AUTOSAR XML (schema 4-2-2)
package /STELLANTIS/EPT/ASWCs
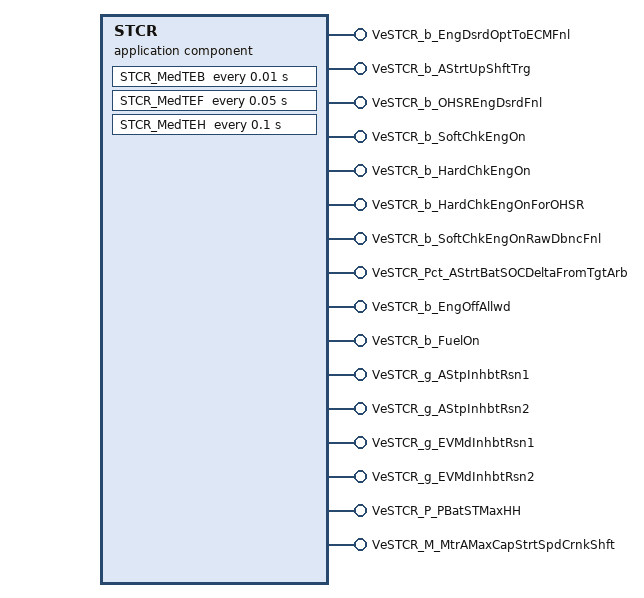
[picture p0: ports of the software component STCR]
  application sw component type STCR
    16 x provide port, all with nonqueued-sender-com-spec{data-element=Value, init-value=0}:
      VeSTCR_b_EngDsrdOptToECMFnl: provided-interface=VeSTCR_b_EngDsrdOptToECMFnl
      VeSTCR_b_AStrtUpShftTrg: provided-interface=VeSTCR_b_AStrtUpShftTrg
      VeSTCR_b_OHSREngDsrdFnl: provided-interface=VeSTCR_b_OHSREngDsrdFnl
      VeSTCR_b_SoftChkEngOn: provided-interface=VeSTCR_b_SoftChkEngOn
      VeSTCR_b_HardChkEngOn: provided-interface=VeSTCR_b_HardChkEngOn
      VeSTCR_b_HardChkEngOnForOHSR: provided-interface=VeSTCR_b_HardChkEngOnForOHSR
      VeSTCR_b_SoftChkEngOnRawDbncFnl: provided-interface=VeSTCR_b_SoftChkEngOnRawDbncFnl
      VeSTCR_Pct_AStrtBatSOCDeltaFromTgtArb: provided-interface=VeSTCR_Pct_AStrtBatSOCDeltaFromTgtArb
      VeSTCR_b_EngOffAllwd: provided-interface=VeSTCR_b_EngOffAllwd
      VeSTCR_b_FuelOn: provided-interface=VeSTCR_b_FuelOn
      VeSTCR_g_AStpInhbtRsn1: provided-interface=VeSTCR_g_AStpInhbtRsn1
      VeSTCR_g_AStpInhbtRsn2: provided-interface=VeSTCR_g_AStpInhbtRsn2
      VeSTCR_g_EVMdInhbtRsn1: provided-interface=VeSTCR_g_EVMdInhbtRsn1
      VeSTCR_g_EVMdInhbtRsn2: provided-interface=VeSTCR_g_EVMdInhbtRsn2
      VeSTCR_P_PBatSTMaxHH: provided-interface=VeSTCR_P_PBatSTMaxHH
      VeSTCR_M_MtrAMaxCapStrtSpdCrnkShft: provided-interface=VeSTCR_M_MtrAMaxCapStrtSpdCrnkShft
    behavior IB_STCR: data-type-mapping=msADTtoIDTMapping, handle-termination-and-restart=NO-SUPPORT
      timing event Event_MedTEB: start-on-event=STCR_MedTEB, period=0.01
      timing event Event_MedTEF: start-on-event=STCR_MedTEF, period=0.05
      timing event Event_MedTEH: start-on-event=STCR_MedTEH, period=0.1
      init event Event_STCR_ac_Init: start-on-event=STCR_ac_Init
      init event Event_PwrOn: start-on-event=STCR_PwrOn
      explicit-inter-runnable-variables:
        6 x data, all with category=VALUE, sw-calibration-access=READ-ONLY, type=Boolean, init-value=0:
          VeSTCR_b_EngOffAlwdSlow_write_IRV
          VeSTCR_b_EngOffAlwdHardChk_write_IRV
          VeSTCR_b_EngOnFuelOn_write_IRV
          VeSTCR_b_SoftChkEngOnFuelOn_write_IRV
          VeSTCR_b_DCOvrld_EngOn_write_IRV
          VeSTCR_b_V2L_EngON_write_IRV
      5 x runnable:
        STCR_ac_Init
        STCR_MedTEB
          data-send-points:
            12 x access:
              OUT_VeSTCR_P_PBatSTMaxHH_Value: accessed-variable=VeSTCR_P_PBatSTMaxHH.Value
              OUT_VeSTCR_b_EngDsrdOptToECMFnl_Value: accessed-variable=VeSTCR_b_EngDsrdOptToECMFnl.Value
              OUT_VeSTCR_b_AStrtUpShftTrg_Value: accessed-variable=VeSTCR_b_AStrtUpShftTrg.Value
              OUT_VeSTCR_b_OHSREngDsrdFnl_Value: accessed-variable=VeSTCR_b_OHSREngDsrdFnl.Value
              OUT_VeSTCR_b_SoftChkEngOn_Value: accessed-variable=VeSTCR_b_SoftChkEngOn.Value
              OUT_VeSTCR_b_SoftChkEngOnRawDbncFnl_Value: accessed-variable=VeSTCR_b_SoftChkEngOnRawDbncFnl.Value
              OUT_VeSTCR_b_EngOffAllwd_Value: accessed-variable=VeSTCR_b_EngOffAllwd.Value
              OUT_VeSTCR_b_FuelOn_Value: accessed-variable=VeSTCR_b_FuelOn.Value
              OUT_VeSTCR_g_AStpInhbtRsn1_Value: accessed-variable=VeSTCR_g_AStpInhbtRsn1.Value
              OUT_VeSTCR_g_AStpInhbtRsn2_Value: accessed-variable=VeSTCR_g_AStpInhbtRsn2.Value
              OUT_VeSTCR_g_EVMdInhbtRsn1_Value: accessed-variable=VeSTCR_g_EVMdInhbtRsn1.Value
              OUT_VeSTCR_g_EVMdInhbtRsn2_Value: accessed-variable=VeSTCR_g_EVMdInhbtRsn2.Value
          read-local-variables:
            4 x access:
              RV_VeSTCR_b_EngOffAlwdHardChk_write_IRV: accessed-variable=VeSTCR_b_EngOffAlwdHardChk_write_IRV
              RV_VeSTCR_b_EngOffAlwdSlow_write_IRV: accessed-variable=VeSTCR_b_EngOffAlwdSlow_write_IRV
              RV_VeSTCR_b_EngOnFuelOn_write_IRV: accessed-variable=VeSTCR_b_EngOnFuelOn_write_IRV
              RV_VeSTCR_b_SoftChkEngOnFuelOn_write_IRV: accessed-variable=VeSTCR_b_SoftChkEngOnFuelOn_write_IRV
          written-local-variables:
            access WV_VeSTCR_b_DCOvrld_EngOn_write_IRV: accessed-variable=VeSTCR_b_DCOvrld_EngOn_write_IRV
            access WV_VeSTCR_b_V2L_EngON_write_IRV: accessed-variable=VeSTCR_b_V2L_EngON_write_IRV
        STCR_MedTEF
          data-send-points:
            access OUT_VeSTCR_b_HardChkEngOn_Value: accessed-variable=VeSTCR_b_HardChkEngOn.Value
            access OUT_VeSTCR_b_HardChkEngOnForOHSR_Value: accessed-variable=VeSTCR_b_HardChkEngOnForOHSR.Value
            access OUT_VeSTCR_M_MtrAMaxCapStrtSpdCrnkShft_Value: accessed-variable=VeSTCR_M_MtrAMaxCapStrtSpdCrnkShft.Value
          written-local-variables:
            access WV_VeSTCR_b_EngOffAlwdHardChk_write_IRV: accessed-variable=VeSTCR_b_EngOffAlwdHardChk_write_IRV
            access WV_VeSTCR_b_EngOnFuelOn_write_IRV: accessed-variable=VeSTCR_b_EngOnFuelOn_write_IRV
        STCR_MedTEH
          data-send-points:
            access OUT_VeSTCR_Pct_AStrtBatSOCDeltaFromTgtArb_Value: accessed-variable=VeSTCR_Pct_AStrtBatSOCDeltaFromTgtArb.Value
          written-local-variables:
            access WV_VeSTCR_b_EngOffAlwdSlow_write_IRV: accessed-variable=VeSTCR_b_EngOffAlwdSlow_write_IRV
            access WV_VeSTCR_b_SoftChkEngOnFuelOn_write_IRV: accessed-variable=VeSTCR_b_SoftChkEngOnFuelOn_write_IRV
        STCR_PwrOn
          data-send-points:
            16 x access:
              OUT_VeSTCR_b_EngDsrdOptToECMFnl_Value: accessed-variable=VeSTCR_b_EngDsrdOptToECMFnl.Value
              OUT_VeSTCR_b_AStrtUpShftTrg_Value: accessed-variable=VeSTCR_b_AStrtUpShftTrg.Value
              OUT_VeSTCR_b_OHSREngDsrdFnl_Value: accessed-variable=VeSTCR_b_OHSREngDsrdFnl.Value
              OUT_VeSTCR_b_SoftChkEngOn_Value: accessed-variable=VeSTCR_b_SoftChkEngOn.Value
              OUT_VeSTCR_b_HardChkEngOn_Value: accessed-variable=VeSTCR_b_HardChkEngOn.Value
              OUT_VeSTCR_b_HardChkEngOnForOHSR_Value: accessed-variable=VeSTCR_b_HardChkEngOnForOHSR.Value
              OUT_VeSTCR_b_SoftChkEngOnRawDbncFnl_Value: accessed-variable=VeSTCR_b_SoftChkEngOnRawDbncFnl.Value
              OUT_VeSTCR_Pct_AStrtBatSOCDeltaFromTgtArb_Value: accessed-variable=VeSTCR_Pct_AStrtBatSOCDeltaFromTgtArb.Value
              OUT_VeSTCR_b_EngOffAllwd_Value: accessed-variable=VeSTCR_b_EngOffAllwd.Value
              OUT_VeSTCR_b_FuelOn_Value: accessed-variable=VeSTCR_b_FuelOn.Value
              OUT_VeSTCR_g_AStpInhbtRsn1_Value: accessed-variable=VeSTCR_g_AStpInhbtRsn1.Value
              OUT_VeSTCR_g_AStpInhbtRsn2_Value: accessed-variable=VeSTCR_g_AStpInhbtRsn2.Value
              OUT_VeSTCR_g_EVMdInhbtRsn1_Value: accessed-variable=VeSTCR_g_EVMdInhbtRsn1.Value
              OUT_VeSTCR_g_EVMdInhbtRsn2_Value: accessed-variable=VeSTCR_g_EVMdInhbtRsn2.Value
              OUT_VeSTCR_P_PBatSTMaxHH_Value: accessed-variable=VeSTCR_P_PBatSTMaxHH.Value
              OUT_VeSTCR_M_MtrAMaxCapStrtSpdCrnkShft_Value: accessed-variable=VeSTCR_M_MtrAMaxCapStrtSpdCrnkShft.Value
          written-local-variables:
            6 x access:
              WV_VeSTCR_b_DCOvrld_EngOn_write_IRV: accessed-variable=VeSTCR_b_DCOvrld_EngOn_write_IRV
              WV_VeSTCR_b_EngOffAlwdHardChk_write_IRV: accessed-variable=VeSTCR_b_EngOffAlwdHardChk_write_IRV
              WV_VeSTCR_b_EngOffAlwdSlow_write_IRV: accessed-variable=VeSTCR_b_EngOffAlwdSlow_write_IRV
              WV_VeSTCR_b_EngOnFuelOn_write_IRV: accessed-variable=VeSTCR_b_EngOnFuelOn_write_IRV
              WV_VeSTCR_b_SoftChkEngOnFuelOn_write_IRV: accessed-variable=VeSTCR_b_SoftChkEngOnFuelOn_write_IRV
              WV_VeSTCR_b_V2L_EngON_write_IRV: accessed-variable=VeSTCR_b_V2L_EngON_write_IRV
      6 x variation point proxy, all with category=CONDITION:
        Variant_STCR_BSGEquipd: condition-access=0
        Variant_STCR_DsblFcn: condition-access=1
        Variant_STCR_P2Equipd: condition-access=0
        Variant_STCR_P2p5Equipd: condition-access=0
        Variant_STCR_P4Equipd: condition-access=0
        Variant_STCR_REEVEquipd: condition-access=0
